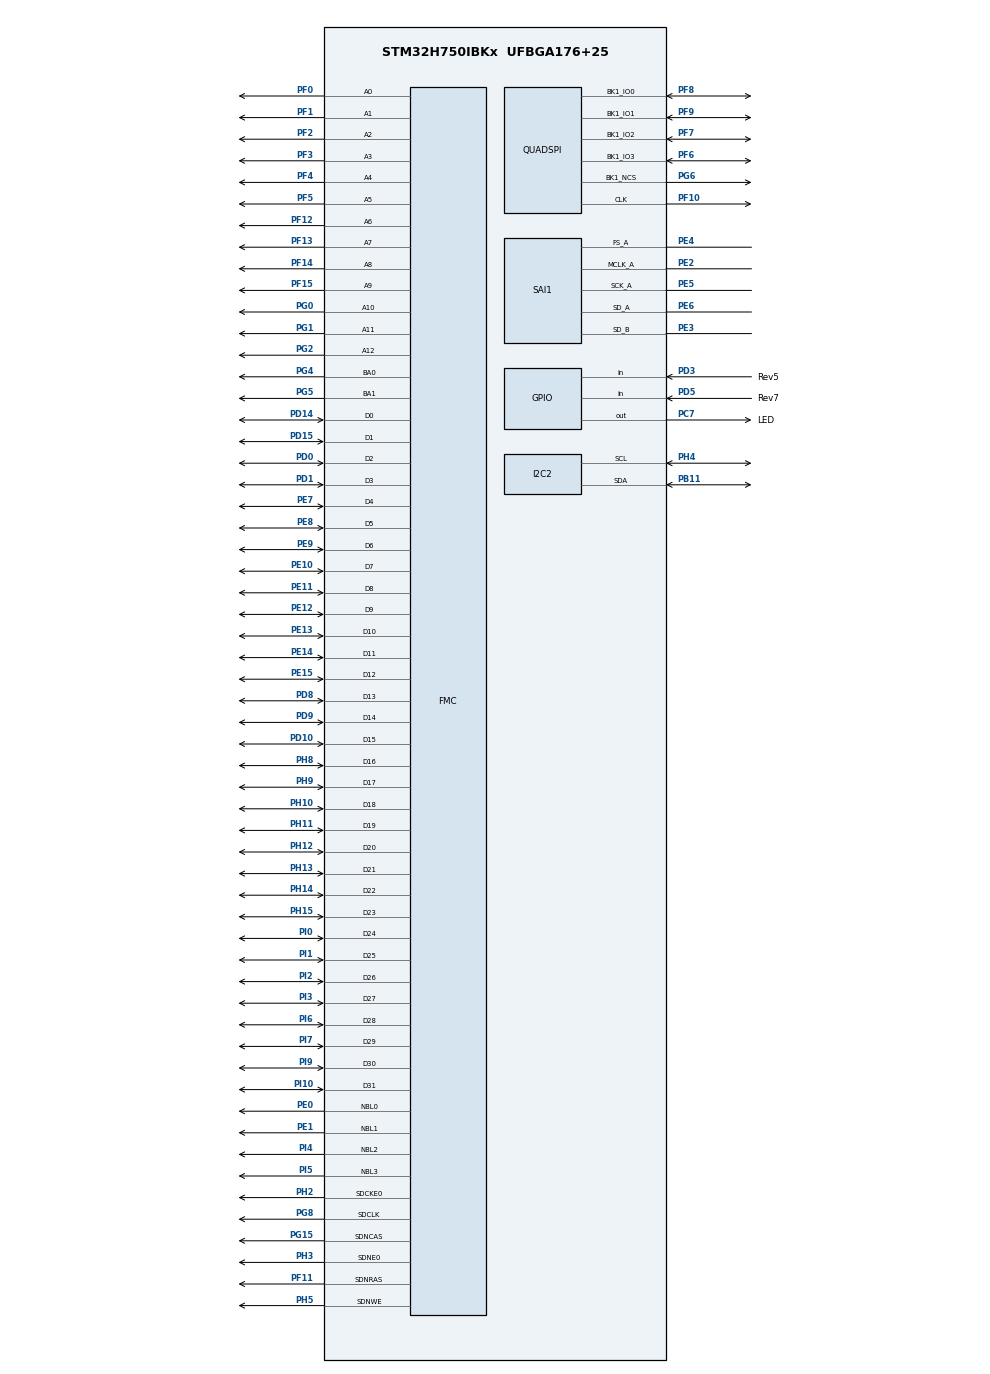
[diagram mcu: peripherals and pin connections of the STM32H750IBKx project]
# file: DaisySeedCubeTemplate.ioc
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CORTEX_M7.AccessPermission_S-Cortex_Memory_Protection_Unit_Region1_Settings_S=MPU_REGION_PRIV_RO
CORTEX_M7.AccessPermission_S-Cortex_Memory_Protection_Unit_Region2_Settings_S=MPU_REGION_FULL_ACCESS
CORTEX_M7.AccessPermission_S-Cortex_Memory_Protection_Unit_Region3_Settings_S=MPU_REGION_FULL_ACCESS
CORTEX_M7.AccessPermission_S-Cortex_Memory_Protection_Unit_Region4_Settings_S=MPU_REGION_FULL_ACCESS
CORTEX_M7.AccessPermission_S-Cortex_Memory_Protection_Unit_Region5_Settings_S=MPU_REGION_FULL_ACCESS
CORTEX_M7.AccessPermission_S-Cortex_Memory_Protection_Unit_Region6_Settings_S=MPU_REGION_FULL_ACCESS
CORTEX_M7.AccessPermission_S-Cortex_Memory_Protection_Unit_Region7_Settings_S=MPU_REGION_PRIV_RO_URO
CORTEX_M7.AccessPermission_S-Cortex_Memory_Protection_Unit_Region8_Settings_S=MPU_REGION_FULL_ACCESS
CORTEX_M7.BaseAddress_S-Cortex_Memory_Protection_Unit_Region1_Settings_S=0x08000000
CORTEX_M7.BaseAddress_S-Cortex_Memory_Protection_Unit_Region2_Settings_S=0x24070800
CORTEX_M7.BaseAddress_S-Cortex_Memory_Protection_Unit_Region3_Settings_S=0x24071000
CORTEX_M7.BaseAddress_S-Cortex_Memory_Protection_Unit_Region4_Settings_S=0x24072000
CORTEX_M7.BaseAddress_S-Cortex_Memory_Protection_Unit_Region5_Settings_S=0x24074000
CORTEX_M7.BaseAddress_S-Cortex_Memory_Protection_Unit_Region6_Settings_S=0x24078000
CORTEX_M7.BaseAddress_S-Cortex_Memory_Protection_Unit_Region7_Settings_S=0x90000000
CORTEX_M7.BaseAddress_S-Cortex_Memory_Protection_Unit_Region8_Settings_S=0xC0000000
CORTEX_M7.DisableExec_S-Cortex_Memory_Protection_Unit_Region7_Settings_S=MPU_INSTRUCTION_ACCESS_DISABLE
CORTEX_M7.DisableExec_S-Cortex_Memory_Protection_Unit_Region8_Settings_S=MPU_INSTRUCTION_ACCESS_DISABLE
CORTEX_M7.Enable_S-Cortex_Memory_Protection_Unit_Region1_Settings_S=MPU_REGION_ENABLE
CORTEX_M7.Enable_S-Cortex_Memory_Protection_Unit_Region2_Settings_S=MPU_REGION_ENABLE
CORTEX_M7.Enable_S-Cortex_Memory_Protection_Unit_Region3_Settings_S=MPU_REGION_ENABLE
CORTEX_M7.Enable_S-Cortex_Memory_Protection_Unit_Region4_Settings_S=MPU_REGION_ENABLE
CORTEX_M7.Enable_S-Cortex_Memory_Protection_Unit_Region5_Settings_S=MPU_REGION_ENABLE
CORTEX_M7.Enable_S-Cortex_Memory_Protection_Unit_Region6_Settings_S=MPU_REGION_ENABLE
CORTEX_M7.Enable_S-Cortex_Memory_Protection_Unit_Region7_Settings_S=MPU_REGION_ENABLE
CORTEX_M7.Enable_S-Cortex_Memory_Protection_Unit_Region8_Settings_S=MPU_REGION_ENABLE
CORTEX_M7.IsCacheable_S-Cortex_Memory_Protection_Unit_Region1_Settings_S=MPU_ACCESS_CACHEABLE
CORTEX_M7.IsShareable_S-Cortex_Memory_Protection_Unit_Region2_Settings_S=MPU_ACCESS_SHAREABLE
CORTEX_M7.IsShareable_S-Cortex_Memory_Protection_Unit_Region3_Settings_S=MPU_ACCESS_SHAREABLE
CORTEX_M7.IsShareable_S-Cortex_Memory_Protection_Unit_Region4_Settings_S=MPU_ACCESS_SHAREABLE
CORTEX_M7.IsShareable_S-Cortex_Memory_Protection_Unit_Region5_Settings_S=MPU_ACCESS_SHAREABLE
CORTEX_M7.IsShareable_S-Cortex_Memory_Protection_Unit_Region6_Settings_S=MPU_ACCESS_SHAREABLE
CORTEX_M7.IsShareable_S-Cortex_Memory_Protection_Unit_Region7_Settings_S=MPU_ACCESS_SHAREABLE
CORTEX_M7.IsShareable_S-Cortex_Memory_Protection_Unit_Region8_Settings_S=MPU_ACCESS_SHAREABLE
CORTEX_M7.MPU_Control=__NULL
CORTEX_M7.Number_S-Cortex_Memory_Protection_Unit_Region2_Settings_S=MPU_REGION_NUMBER2
CORTEX_M7.Number_S-Cortex_Memory_Protection_Unit_Region3_Settings_S=MPU_REGION_NUMBER3
CORTEX_M7.Number_S-Cortex_Memory_Protection_Unit_Region4_Settings_S=MPU_REGION_NUMBER4
CORTEX_M7.Number_S-Cortex_Memory_Protection_Unit_Region5_Settings_S=MPU_REGION_NUMBER5
CORTEX_M7.Number_S-Cortex_Memory_Protection_Unit_Region6_Settings_S=MPU_REGION_NUMBER6
CORTEX_M7.Number_S-Cortex_Memory_Protection_Unit_Region7_Settings_S=MPU_REGION_NUMBER7
CORTEX_M7.Number_S-Cortex_Memory_Protection_Unit_Region8_Settings_S=MPU_REGION_NUMBER8
CORTEX_M7.Size_S-Cortex_Memory_Protection_Unit_Region1_Settings_S=MPU_REGION_SIZE_128KB
CORTEX_M7.Size_S-Cortex_Memory_Protection_Unit_Region2_Settings_S=MPU_REGION_SIZE_2KB
CORTEX_M7.Size_S-Cortex_Memory_Protection_Unit_Region3_Settings_S=MPU_REGION_SIZE_4KB
CORTEX_M7.Size_S-Cortex_Memory_Protection_Unit_Region4_Settings_S=MPU_REGION_SIZE_8KB
CORTEX_M7.Size_S-Cortex_Memory_Protection_Unit_Region5_Settings_S=MPU_REGION_SIZE_16KB
CORTEX_M7.Size_S-Cortex_Memory_Protection_Unit_Region6_Settings_S=MPU_REGION_SIZE_32KB
CORTEX_M7.Size_S-Cortex_Memory_Protection_Unit_Region7_Settings_S=MPU_REGION_SIZE_8MB
CORTEX_M7.Size_S-Cortex_Memory_Protection_Unit_Region8_Settings_S=MPU_REGION_SIZE_64MB
CORTEX_M7.TypeExtField_S-Cortex_Memory_Protection_Unit_Region2_Settings_S=MPU_TEX_LEVEL1
CORTEX_M7.TypeExtField_S-Cortex_Memory_Protection_Unit_Region3_Settings_S=MPU_TEX_LEVEL1
CORTEX_M7.TypeExtField_S-Cortex_Memory_Protection_Unit_Region4_Settings_S=MPU_TEX_LEVEL1
CORTEX_M7.TypeExtField_S-Cortex_Memory_Protection_Unit_Region5_Settings_S=MPU_TEX_LEVEL1
CORTEX_M7.TypeExtField_S-Cortex_Memory_Protection_Unit_Region6_Settings_S=MPU_TEX_LEVEL1
CORTEX_M7.TypeExtField_S-Cortex_Memory_Protection_Unit_Region7_Settings_S=MPU_TEX_LEVEL1
CORTEX_M7.TypeExtField_S-Cortex_Memory_Protection_Unit_Region8_Settings_S=MPU_TEX_LEVEL1
CORTEX_M7.default_mode_Activation=0
Dma.Request0=SAI1_A
Dma.Request1=SAI1_B
Dma.SAI1_A.0.Direction=DMA_MEMORY_TO_PERIPH
Dma.SAI1_A.0.EventEnable=DISABLE
Dma.SAI1_A.0.FIFOMode=DMA_FIFOMODE_DISABLE
Dma.SAI1_A.0.Instance=DMA1_Stream0
Dma.SAI1_A.0.MemDataAlignment=DMA_MDATAALIGN_WORD
Dma.SAI1_A.0.MemInc=DMA_MINC_ENABLE
Dma.SAI1_A.0.Mode=DMA_CIRCULAR
Dma.SAI1_A.0.PeriphDataAlignment=DMA_PDATAALIGN_WORD
Dma.SAI1_A.0.PeriphInc=DMA_PINC_DISABLE
Dma.SAI1_A.0.Polarity=HAL_DMAMUX_REQ_GEN_RISING
Dma.SAI1_A.0.Priority=DMA_PRIORITY_HIGH
Dma.SAI1_A.0.RequestNumber=1
Dma.SAI1_A.0.SignalID=NONE
Dma.SAI1_A.0.SyncEnable=DISABLE
Dma.SAI1_A.0.SyncPolarity=HAL_DMAMUX_SYNC_NO_EVENT
Dma.SAI1_A.0.SyncRequestNumber=1
Dma.SAI1_A.0.SyncSignalID=NONE
Dma.SAI1_B.1.Direction=DMA_PERIPH_TO_MEMORY
Dma.SAI1_B.1.EventEnable=DISABLE
Dma.SAI1_B.1.FIFOMode=DMA_FIFOMODE_DISABLE
Dma.SAI1_B.1.Instance=DMA1_Stream1
Dma.SAI1_B.1.MemDataAlignment=DMA_MDATAALIGN_WORD
Dma.SAI1_B.1.MemInc=DMA_MINC_ENABLE
Dma.SAI1_B.1.Mode=DMA_CIRCULAR
Dma.SAI1_B.1.PeriphDataAlignment=DMA_PDATAALIGN_WORD
Dma.SAI1_B.1.PeriphInc=DMA_PINC_DISABLE
Dma.SAI1_B.1.Polarity=HAL_DMAMUX_REQ_GEN_RISING
Dma.SAI1_B.1.Priority=DMA_PRIORITY_LOW
Dma.SAI1_B.1.RequestNumber=1
Dma.SAI1_B.1.SignalID=NONE
Dma.SAI1_B.1.SyncEnable=DISABLE
Dma.SAI1_B.1.SyncPolarity=HAL_DMAMUX_SYNC_NO_EVENT
Dma.SAI1_B.1.SyncRequestNumber=1
Dma.SAI1_B.1.SyncSignalID=NONE
FMC.CASLatency1=FMC_SDRAM_CAS_LATENCY_3
FMC.ColumnBitsNumber1=FMC_SDRAM_COLUMN_BITS_NUM_9
FMC.ExitSelfRefreshDelay1=7
FMC.LoadToActiveDelay1=2
FMC.RCDDelay1=10
FMC.ReadBurst1=FMC_SDRAM_RBURST_ENABLE
FMC.ReadPipeDelay1=FMC_SDRAM_RPIPE_DELAY_0
FMC.RowCycleDelay1=8
FMC.SDClockPeriod1=FMC_SDRAM_CLOCK_PERIOD_2
FMC.SelfRefreshTime1=4
FMC.WriteRecoveryTime1=3
I2C2.Timing=0x307075B1
Mcu.Family=STM32H7
Mcu.Name=STM32H750IBKx
Mcu.Package=UFBGA176+25
NVIC.DMA1_Stream0_IRQn=true\:0\:0\:false\:false\:true\:false\:true\:true
NVIC.DMA1_Stream1_IRQn=true\:0\:0\:false\:false\:true\:false\:true\:true
NVIC.FMC_IRQn=true\:0\:0\:false\:false\:true\:true\:true\:true
NVIC.I2C2_ER_IRQn=true\:0\:0\:false\:false\:true\:true\:true\:true
NVIC.I2C2_EV_IRQn=true\:0\:0\:false\:false\:true\:true\:true\:true
NVIC.PriorityGroup=NVIC_PRIORITYGROUP_4
NVIC.QUADSPI_IRQn=true\:0\:0\:false\:false\:true\:true\:true\:true
PA13\ (JTMS/SWDIO).Mode=JTAG_4_pins
PA13\ (JTMS/SWDIO).Signal=DEBUG_JTMS-SWDIO
PA14\ (JTCK/SWCLK).Mode=JTAG_4_pins
PA14\ (JTCK/SWCLK).Signal=DEBUG_JTCK-SWCLK
PA15\ (JTDI).Mode=JTAG_4_pins
PA15\ (JTDI).Signal=DEBUG_JTDI
PB11.Mode=I2C
PB11.Signal=I2C2_SDA
PB3\ (JTDO/TRACESWO).Mode=JTAG_4_pins
PB3\ (JTDO/TRACESWO).Signal=DEBUG_JTDO-SWO
PC7.GPIO_Label=LED
PC7.Signal=GPIO_Output
PD0.Signal=FMC_D2_DA2
PD1.Signal=FMC_D3_DA3
PD10.Signal=FMC_D15_DA15
PD14.Signal=FMC_D0_DA0
PD15.Signal=FMC_D1_DA1
PD3.GPIO_Label=Rev5
PD3.GPIO_PuPd=GPIO_PULLUP
PD3.Signal=GPIO_Input
PD5.GPIO_Label=Rev7
PD5.GPIO_PuPd=GPIO_PULLUP
PD5.Signal=GPIO_Input
PD8.Signal=FMC_D13_DA13
PD9.Signal=FMC_D14_DA14
PE0.Signal=FMC_NBL0
PE1.Signal=FMC_NBL1
PE10.Signal=FMC_D7_DA7
PE11.Signal=FMC_D8_DA8
PE12.Signal=FMC_D9_DA9
PE13.Signal=FMC_D10_DA10
PE14.Signal=FMC_D11_DA11
PE15.Signal=FMC_D12_DA12
PE2.GPIO_Speed=GPIO_SPEED_FREQ_VERY_HIGH
PE2.Mode=SAI_A_MasterWithClock
PE2.Signal=SAI1_MCLK_A
PE3.GPIO_Speed=GPIO_SPEED_FREQ_VERY_HIGH
PE3.Mode=SAI_B_SyncSlave
PE3.Signal=SAI1_SD_B
PE4.GPIO_Speed=GPIO_SPEED_FREQ_VERY_HIGH
PE4.Mode=SAI_A_MasterWithClock
PE4.Signal=SAI1_FS_A
PE5.GPIO_Speed=GPIO_SPEED_FREQ_VERY_HIGH
PE5.Mode=SAI_A_MasterWithClock
PE5.Signal=SAI1_SCK_A
PE6.GPIO_Speed=GPIO_SPEED_FREQ_VERY_HIGH
PE6.Mode=SAI_A_MasterWithClock
PE6.Signal=SAI1_SD_A
PE7.Signal=FMC_D4_DA4
PE8.Signal=FMC_D5_DA5
PE9.Signal=FMC_D6_DA6
PF0.Signal=FMC_A0
PF1.Signal=FMC_A1
PF10.GPIO_Speed=GPIO_SPEED_FREQ_VERY_HIGH
PF10.Mode=Single Bank 1
PF10.Signal=QUADSPI_CLK
PF11.Signal=FMC_SDNRAS
PF12.Signal=FMC_A6
PF13.Signal=FMC_A7
PF14.Signal=FMC_A8
PF15.Signal=FMC_A9
PF2.Signal=FMC_A2
PF3.Signal=FMC_A3
PF4.Signal=FMC_A4
PF5.Signal=FMC_A5
PF6.GPIO_Speed=GPIO_SPEED_FREQ_VERY_HIGH
PF6.Mode=Single Bank 1
PF6.Signal=QUADSPI_BK1_IO3
PF7.GPIO_Speed=GPIO_SPEED_FREQ_VERY_HIGH
PF7.Mode=Single Bank 1
PF7.Signal=QUADSPI_BK1_IO2
PF8.GPIO_Speed=GPIO_SPEED_FREQ_VERY_HIGH
PF8.Mode=Single Bank 1
PF8.Signal=QUADSPI_BK1_IO0
PF9.GPIO_Speed=GPIO_SPEED_FREQ_VERY_HIGH
PF9.Mode=Single Bank 1
PF9.Signal=QUADSPI_BK1_IO1
PG0.Signal=FMC_A10
PG1.Signal=FMC_A11
PG15.Signal=FMC_SDNCAS
PG2.Signal=FMC_A12
PG4.Signal=FMC_A14_BA0
PG5.Signal=FMC_A15_BA1
PG6.GPIO_Speed=GPIO_SPEED_FREQ_VERY_HIGH
PG6.Mode=Single Bank 1
PG6.Signal=QUADSPI_BK1_NCS
PG8.Signal=FMC_SDCLK
PH0-OSC_IN\ (PH0).Mode=HSE-External-Oscillator
PH0-OSC_IN\ (PH0).Signal=RCC_OSC_IN
PH1-OSC_OUT\ (PH1).Mode=HSE-External-Oscillator
PH1-OSC_OUT\ (PH1).Signal=RCC_OSC_OUT
PH10.Signal=FMC_D18
PH11.Signal=FMC_D19
PH12.Signal=FMC_D20
PH13.Signal=FMC_D21
PH14.Signal=FMC_D22
PH15.Signal=FMC_D23
PH2.Mode=SdramChipSelect1_1
PH2.Signal=FMC_SDCKE0
PH3.Mode=SdramChipSelect1_1
PH3.Signal=FMC_SDNE0
PH4.Mode=I2C
PH4.Signal=I2C2_SCL
PH5.Signal=FMC_SDNWE
PH8.Signal=FMC_D16
PH9.Signal=FMC_D17
PI0.Signal=FMC_D24
PI1.Signal=FMC_D25
PI10.Signal=FMC_D31
PI2.Signal=FMC_D26
PI3.Signal=FMC_D27
PI4.Signal=FMC_NBL2
PI5.Signal=FMC_NBL3
PI6.Signal=FMC_D28
PI7.Signal=FMC_D29
PI9.Signal=FMC_D30
ProjectManager.HeapSize=0x8000
ProjectManager.StackSize=0x2000
ProjectManager.TargetToolchain=STM32CubeIDE
QUADSPI.ChipSelectHighTime=QSPI_CS_HIGH_TIME_1_CYCLE
QUADSPI.ClockPrescaler=2
QUADSPI.DeviceType=SPI_DEVICE_FLASH
QUADSPI.FlashSize=22
QUADSPI.SampleShifting=QSPI_SAMPLE_SHIFTING_HALFCYCLE
RCC.ADCFreq_Value=12288026.75189394
RCC.APB1Freq_Value=120000000
RCC.APB2Freq_Value=120000000
RCC.APB3Freq_Value=120000000
RCC.APB4Freq_Value=120000000
RCC.CortexFreq_Value=480000000
RCC.D1PPRE=RCC_APB3_DIV2
RCC.D2PPRE1=RCC_APB1_DIV2
RCC.D2PPRE2=RCC_APB2_DIV2
RCC.D3PPRE=RCC_APB4_DIV2
RCC.DIVM1=4
RCC.DIVM2=1
RCC.DIVN1=240
RCC.DIVN2=50
RCC.DIVP2=66
RCC.DIVQ1=6
RCC.DIVR1=8
RCC.HCLKFreq_Value=240000000
RCC.HPRE=RCC_HCLK_DIV2
RCC.HSE_VALUE=16000000
RCC.PLL2FRACN=5637
RCC.PLLFRACN=0
RCC.PLLSourceVirtual=RCC_PLLSOURCE_HSE
RCC.SAI1CLockSelection=RCC_SAI1CLKSOURCE_PLL2
RCC.SYSCLKFreq_VALUE=480000000
RCC.SYSCLKSource=RCC_SYSCLKSOURCE_PLLCLK
RCC.USBFreq_Value=160000000
SAI1.AudioFrequency-SAI_A_MasterWithClock=SAI_AUDIO_FREQUENCY_48K
SAI1.BasicDataSize-SAI_A_MasterWithClock=SAI_PROTOCOL_DATASIZE_24BIT
SAI1.BasicDataSize-SAI_B_SyncSlave=SAI_PROTOCOL_DATASIZE_24BIT
SAI1.BasicProtocol-SAI_A_MasterWithClock=SAI_I2S_MSBJUSTIFIED
SAI1.BasicProtocol-SAI_B_SyncSlave=SAI_I2S_MSBJUSTIFIED
SAI1.ErrorAudioFreq-SAI_A_MasterWithClock=0.0 %
SAI1.InitProtocol-SAI_A_MasterWithClock=Enable
SAI1.InitProtocol-SAI_B_SyncSlave=Enable
SAI1.Instance-SAI_A_MasterWithClock=SAI$Index_Block_A
SAI1.Instance-SAI_B_SyncSlave=SAI$Index_Block_B
SAI1.MClockEnable-SAI_A_MasterWithClock=SAI_MASTERCLOCK_ENABLE
SAI1.NoDivider-SAI_A_MasterWithClock=SAI_MCK_OVERSAMPLING_DISABLE
SAI1.RealAudioFreq-SAI_A_MasterWithClock=48.0 KHz
SAI1.VirtualMode-SAI_A_MasterWithClock=VM_MASTER
SAI1.VirtualMode-SAI_B_SyncSlave=VM_SLAVE
SAI1.VirtualProtocol-SAI_A_BASIC=VM_BASIC_PROTOCOL
SAI1.VirtualProtocol-SAI_B_BASIC=VM_BASIC_PROTOCOL
SH.FMC_A0.0=FMC_A0,13b-sda1
SH.FMC_A1.0=FMC_A1,13b-sda1
SH.FMC_A10.0=FMC_A10,13b-sda1
SH.FMC_A11.0=FMC_A11,13b-sda1
SH.FMC_A12.0=FMC_A12,13b-sda1
SH.FMC_A14_BA0.0=FMC_BA0,FourSdramBanks1
SH.FMC_A15_BA1.0=FMC_BA1,FourSdramBanks1
SH.FMC_A2.0=FMC_A2,13b-sda1
SH.FMC_A3.0=FMC_A3,13b-sda1
SH.FMC_A4.0=FMC_A4,13b-sda1
SH.FMC_A5.0=FMC_A5,13b-sda1
SH.FMC_A6.0=FMC_A6,13b-sda1
SH.FMC_A7.0=FMC_A7,13b-sda1
SH.FMC_A8.0=FMC_A8,13b-sda1
SH.FMC_A9.0=FMC_A9,13b-sda1
SH.FMC_D0_DA0.0=FMC_D0,sd-32b-d1
SH.FMC_D10_DA10.0=FMC_D10,sd-32b-d1
SH.FMC_D11_DA11.0=FMC_D11,sd-32b-d1
SH.FMC_D12_DA12.0=FMC_D12,sd-32b-d1
SH.FMC_D13_DA13.0=FMC_D13,sd-32b-d1
SH.FMC_D14_DA14.0=FMC_D14,sd-32b-d1
SH.FMC_D15_DA15.0=FMC_D15,sd-32b-d1
SH.FMC_D16.0=FMC_D16,sd-32b-d1
SH.FMC_D17.0=FMC_D17,sd-32b-d1
SH.FMC_D18.0=FMC_D18,sd-32b-d1
SH.FMC_D19.0=FMC_D19,sd-32b-d1
SH.FMC_D1_DA1.0=FMC_D1,sd-32b-d1
SH.FMC_D20.0=FMC_D20,sd-32b-d1
SH.FMC_D21.0=FMC_D21,sd-32b-d1
SH.FMC_D22.0=FMC_D22,sd-32b-d1
SH.FMC_D23.0=FMC_D23,sd-32b-d1
SH.FMC_D24.0=FMC_D24,sd-32b-d1
SH.FMC_D25.0=FMC_D25,sd-32b-d1
SH.FMC_D26.0=FMC_D26,sd-32b-d1
SH.FMC_D27.0=FMC_D27,sd-32b-d1
SH.FMC_D28.0=FMC_D28,sd-32b-d1
SH.FMC_D29.0=FMC_D29,sd-32b-d1
SH.FMC_D2_DA2.0=FMC_D2,sd-32b-d1
SH.FMC_D30.0=FMC_D30,sd-32b-d1
SH.FMC_D31.0=FMC_D31,sd-32b-d1
SH.FMC_D3_DA3.0=FMC_D3,sd-32b-d1
SH.FMC_D4_DA4.0=FMC_D4,sd-32b-d1
SH.FMC_D5_DA5.0=FMC_D5,sd-32b-d1
SH.FMC_D6_DA6.0=FMC_D6,sd-32b-d1
SH.FMC_D7_DA7.0=FMC_D7,sd-32b-d1
SH.FMC_D8_DA8.0=FMC_D8,sd-32b-d1
SH.FMC_D9_DA9.0=FMC_D9,sd-32b-d1
SH.FMC_NBL0.0=FMC_NBL0,Sd4ByteEnable1
SH.FMC_NBL1.0=FMC_NBL1,Sd4ByteEnable1
SH.FMC_NBL2.0=FMC_NBL2,Sd4ByteEnable1
SH.FMC_NBL3.0=FMC_NBL3,Sd4ByteEnable1
SH.FMC_SDCLK.0=FMC_SDCLK,13b-sda1
SH.FMC_SDNCAS.0=FMC_SDNCAS,13b-sda1
SH.FMC_SDNRAS.0=FMC_SDNRAS,13b-sda1
SH.FMC_SDNWE.0=FMC_SDNWE,13b-sda1
VP_MEMORYMAP_VS_MEMORYMAP.Mode=CurAppReg
VP_SAI1_VP_$IpInstance_SAIA_SAI_BASIC.Mode=SAI_A_BASIC
VP_SAI1_VP_$IpInstance_SAIB_SAI_BASIC.Mode=SAI_B_BASIC
board=custom

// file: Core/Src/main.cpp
/* USER CODE BEGIN Header */
/**
  ******************************************************************************
  * @file           : main.c
  * @brief          : Main program body
  ******************************************************************************
  * @attention
  *
  * Copyright (c) 2025 STMicroelectronics.
  * All rights reserved.
  *
  * This software is licensed under terms that can be found in the LICENSE file
  * in the root directory of this software component.
  * If no LICENSE file comes with this software, it is provided AS-IS.
  *
  ******************************************************************************
  */
/* USER CODE END Header */
#include "main.h"

/* USER CODE BEGIN Includes */
#include "cIS25LPxxx.h"
#include "cWM8731.h"
/* USER CODE END Includes */

I2C_HandleTypeDef hi2c2;

QSPI_HandleTypeDef hqspi;

SAI_HandleTypeDef hsai_BlockA1;
SAI_HandleTypeDef hsai_BlockB1;
DMA_HandleTypeDef hdma_sai1_a;
DMA_HandleTypeDef hdma_sai1_b;

SDRAM_HandleTypeDef hsdram1;

void SystemClock_Config(void);
void PeriphCommonClock_Config(void);

/* USER CODE BEGIN 0 */

// == DAD =================================================================

extern "C" void DAD_MPU_Config(void);

//QFlash
Dad::cIS25LPxxx __Flash;

// Revision
enum HardRev{
	Rev5,
	Rev7
}__HardRev;

// WM8731 management for Rev5
Dad::cWM8731  __WM8731;

// Test SDRAM
SDRAM_SECTION uint8_t TabSRAMTest[100];

//------------------------------------------------------------------
// AudioCallback
uint32_t __CT=0; 			// Cycle counter
							// - Used in main loop to blink an activity LED
 	 	 	 	 	 	 	// - The LED blink rate indicates proper callback execution
ITCM void AudioCallback(AudioBuffer *pIn, AudioBuffer *pOut){
	for (size_t i = 0; i < AUDIO_BUFFER_SIZE; i++)
	{
		pOut->Right = pIn->Right;
		pOut->Left = pIn->Left;
		pOut++;
		pIn++;
	}

    // Increment cycle counter for visual feedback:
    __CT++;
}

// ------------------------------------------------------------------------
// Function to copy code from Flash to ITCM RAM at startup
// This ensures that critical code runs from ITCM for better performance.
//
// Any critical function that needs to run from ITCM must be preceded by the ITCM macro.
// Example usage:
//     ITCM void CriticalFunction() {
//         // Time-sensitive code
//     }
// ------------------------------------------------------------------------
#pragma GCC push_options
#pragma GCC optimize ("O0")
extern uint32_t __sITCM, __eITCM, __lITCM;  // Linker symbols for ITCM section

void Copy_ITCM_Code(void) {
    uint32_t *pSrc = &__lITCM;  // Source address in Flash (load address)
    uint32_t *pDest = &__sITCM; // Destination address in ITCM RAM (start of ITCM)

    // Copy the code section from Flash to ITCM RAM
    while (pDest < &__eITCM) {
        *pDest++ = *pSrc++;
    }
}
#pragma GCC pop_options

// ------------------------------------------------------------------------
// Specific initialization for hardware revision 5:
// input and output signals are inverted compared to revision 7."
extern "C" void HAL_SAIRev5_MspInit(SAI_HandleTypeDef* hsai);
void MX_SAI1Rev5_Init(void)
{
  HAL_SAI_RegisterCallback(&hsai_BlockA1, HAL_SAI_MSPINIT_CB_ID,HAL_SAIRev5_MspInit);
  HAL_SAI_RegisterCallback(&hsai_BlockB1, HAL_SAI_MSPINIT_CB_ID,HAL_SAIRev5_MspInit);

  hsai_BlockA1.Instance = SAI1_Block_A;
  // ===============================================
  // Dad Change TX->RX
  hsai_BlockA1.Init.AudioMode = SAI_MODEMASTER_RX;
  hsai_BlockA1.Init.Synchro = SAI_ASYNCHRONOUS;
  hsai_BlockA1.Init.OutputDrive = SAI_OUTPUTDRIVE_DISABLE;
  hsai_BlockA1.Init.NoDivider = SAI_MCK_OVERSAMPLING_DISABLE;
  hsai_BlockA1.Init.MckOverSampling = SAI_MCK_OVERSAMPLING_DISABLE;
  hsai_BlockA1.Init.FIFOThreshold = SAI_FIFOTHRESHOLD_EMPTY;
  hsai_BlockA1.Init.AudioFrequency = SAI_AUDIO_FREQUENCY_48K;
  hsai_BlockA1.Init.SynchroExt = SAI_SYNCEXT_DISABLE;
  hsai_BlockA1.Init.MonoStereoMode = SAI_STEREOMODE;
  hsai_BlockA1.Init.CompandingMode = SAI_NOCOMPANDING;
  hsai_BlockA1.Init.TriState = SAI_OUTPUT_NOTRELEASED;
  if (HAL_SAI_InitProtocol(&hsai_BlockA1, SAI_I2S_MSBJUSTIFIED, SAI_PROTOCOL_DATASIZE_24BIT, 2) != HAL_OK)
  {
    Error_Handler();
  }
  hsai_BlockB1.Instance = SAI1_Block_B;
  // ===============================================
  // Dad Change RC->TX
  hsai_BlockB1.Init.AudioMode = SAI_MODESLAVE_TX;
  hsai_BlockB1.Init.Synchro = SAI_SYNCHRONOUS;
  hsai_BlockB1.Init.OutputDrive = SAI_OUTPUTDRIVE_DISABLE;
  hsai_BlockB1.Init.MckOverSampling = SAI_MCK_OVERSAMPLING_DISABLE;
  hsai_BlockB1.Init.FIFOThreshold = SAI_FIFOTHRESHOLD_EMPTY;
  hsai_BlockB1.Init.SynchroExt = SAI_SYNCEXT_DISABLE;
  hsai_BlockB1.Init.MonoStereoMode = SAI_STEREOMODE;
  hsai_BlockB1.Init.CompandingMode = SAI_NOCOMPANDING;
  hsai_BlockB1.Init.TriState = SAI_OUTPUT_NOTRELEASED;
  if (HAL_SAI_InitProtocol(&hsai_BlockB1, SAI_I2S_MSBJUSTIFIED, SAI_PROTOCOL_DATASIZE_24BIT, 2) != HAL_OK)
  {
    Error_Handler();
  }
}

// ===================================================================

/* USER CODE END 0 */

int main(void)
{

  /* USER CODE BEGIN 1 */

// ==** DAD **=================================================================

#ifdef USE_RAM
	SCB->VTOR = 0x24000000;
#endif

// ===================================================================

  /* USER CODE END 1 */

  /* MCU Configuration--------------------------------------------------------*/

  /* Reset of all peripherals, Initializes the Flash interface and the Systick. */
  HAL_Init();

  /* Configure the system clock */
  SystemClock_Config();

  /* Configure the peripherals common clocks */
  PeriphCommonClock_Config();

  /* Initialize all configured peripherals */
  MX_GPIO_Init();
  MX_DMA_Init();
  MX_QUADSPI_Init();
  MX_FMC_Init();
  /* USER CODE BEGIN 2 */

// ==** DAD **=================================================================
  __Flash.Init(&hqspi);
  Copy_ITCM_Code();
  DAD_MPU_Config();
  SCB_EnableICache();
  SCB_EnableDCache();

  // Revision configuration
  MX_DMA_Init();
  if(GPIO_PIN_RESET == HAL_GPIO_ReadPin(Rev5_GPIO_Port, Rev5_Pin)){
	  __HardRev = Rev5;
	  MX_I2C2_Init();
	  MX_SAI1Rev5_Init();
	  __WM8731.Initialize(&hi2c2);
  }else if(GPIO_PIN_RESET == HAL_GPIO_ReadPin(Rev7_GPIO_Port, Rev7_Pin)){
	  __HardRev = Rev7;
	  MX_SAI1_Init();
	  GPIO_InitTypeDef GPIO_InitStruct = {0};
	  GPIO_InitStruct.Pin = GPIO_PIN_11;
	  GPIO_InitStruct.Mode = GPIO_MODE_OUTPUT_PP;
	  GPIO_InitStruct.Pull = GPIO_NOPULL;
	  GPIO_InitStruct.Speed = GPIO_SPEED_FREQ_LOW;
	  HAL_GPIO_Init(GPIOB, &GPIO_InitStruct);
	  HAL_GPIO_WritePin(GPIOB, GPIO_PIN_11, GPIO_PIN_RESET);
  }else{
	  // Revision not supported
	  while(1){
		    HAL_GPIO_TogglePin(LED_GPIO_Port, LED_Pin);
			HAL_Delay(100);
	  }
  }
  StartAudio();

  // Test SDRAM
  for(uint8_t Index=0; Index < 100; Index++){
	TabSRAMTest[Index] = Index;
  }

// ===================================================================

  /* USER CODE END 2 */

  /* Infinite loop */
  while (1)
  {

    /* USER CODE BEGIN 3 */

// ==** DAD **=================================================================

      // LED blinking: indicates that the audio loop is operating correctly.
      if(__CT >= (uint32_t) (((float)SAMPLING_RATE / 4.0f)  * 0.5f)){
    	  __CT =0;
    	  HAL_GPIO_TogglePin(LED_GPIO_Port, LED_Pin);
      }

	  HAL_Delay(100);

// ===================================================================

  }
  /* USER CODE END 3 */
}

void SystemClock_Config(void)
{
  RCC_OscInitTypeDef RCC_OscInitStruct = {0};
  RCC_ClkInitTypeDef RCC_ClkInitStruct = {0};

  /** Supply configuration update enable
  */
  HAL_PWREx_ConfigSupply(PWR_LDO_SUPPLY);

  /** Configure the main internal regulator output voltage
  */
  __HAL_PWR_VOLTAGESCALING_CONFIG(PWR_REGULATOR_VOLTAGE_SCALE0);

  while(!__HAL_PWR_GET_FLAG(PWR_FLAG_VOSRDY)) {}

  /** Initializes the RCC Oscillators according to the specified parameters
  * in the RCC_OscInitTypeDef structure.
  */
  RCC_OscInitStruct.OscillatorType = RCC_OSCILLATORTYPE_HSE;
  RCC_OscInitStruct.HSEState = RCC_HSE_ON;
  RCC_OscInitStruct.PLL.PLLState = RCC_PLL_ON;
  RCC_OscInitStruct.PLL.PLLSource = RCC_PLLSOURCE_HSE;
  RCC_OscInitStruct.PLL.PLLM = 4;
  RCC_OscInitStruct.PLL.PLLN = 240;
  RCC_OscInitStruct.PLL.PLLP = 2;
  RCC_OscInitStruct.PLL.PLLQ = 6;
  RCC_OscInitStruct.PLL.PLLR = 8;
  RCC_OscInitStruct.PLL.PLLRGE = RCC_PLL1VCIRANGE_2;
  RCC_OscInitStruct.PLL.PLLVCOSEL = RCC_PLL1VCOWIDE;
  RCC_OscInitStruct.PLL.PLLFRACN = 0;
  if (HAL_RCC_OscConfig(&RCC_OscInitStruct) != HAL_OK)
  {
    Error_Handler();
  }

  /** Initializes the CPU, AHB and APB buses clocks
  */
  RCC_ClkInitStruct.ClockType = RCC_CLOCKTYPE_HCLK|RCC_CLOCKTYPE_SYSCLK
                              |RCC_CLOCKTYPE_PCLK1|RCC_CLOCKTYPE_PCLK2
                              |RCC_CLOCKTYPE_D3PCLK1|RCC_CLOCKTYPE_D1PCLK1;
  RCC_ClkInitStruct.SYSCLKSource = RCC_SYSCLKSOURCE_PLLCLK;
  RCC_ClkInitStruct.SYSCLKDivider = RCC_SYSCLK_DIV1;
  RCC_ClkInitStruct.AHBCLKDivider = RCC_HCLK_DIV2;
  RCC_ClkInitStruct.APB3CLKDivider = RCC_APB3_DIV2;
  RCC_ClkInitStruct.APB1CLKDivider = RCC_APB1_DIV2;
  RCC_ClkInitStruct.APB2CLKDivider = RCC_APB2_DIV2;
  RCC_ClkInitStruct.APB4CLKDivider = RCC_APB4_DIV2;

  if (HAL_RCC_ClockConfig(&RCC_ClkInitStruct, FLASH_LATENCY_4) != HAL_OK)
  {
    Error_Handler();
  }
}

void PeriphCommonClock_Config(void)
{
  RCC_PeriphCLKInitTypeDef PeriphClkInitStruct = {0};

  /** Initializes the peripherals clock
  */
  PeriphClkInitStruct.PeriphClockSelection = RCC_PERIPHCLK_SAI1;
  PeriphClkInitStruct.PLL2.PLL2M = 1;
  PeriphClkInitStruct.PLL2.PLL2N = 50;
  PeriphClkInitStruct.PLL2.PLL2P = 66;
  PeriphClkInitStruct.PLL2.PLL2Q = 2;
  PeriphClkInitStruct.PLL2.PLL2R = 2;
  PeriphClkInitStruct.PLL2.PLL2RGE = RCC_PLL2VCIRANGE_3;
  PeriphClkInitStruct.PLL2.PLL2VCOSEL = RCC_PLL2VCOWIDE;
  PeriphClkInitStruct.PLL2.PLL2FRACN = 5637;
  PeriphClkInitStruct.Sai1ClockSelection = RCC_SAI1CLKSOURCE_PLL2;
  if (HAL_RCCEx_PeriphCLKConfig(&PeriphClkInitStruct) != HAL_OK)
  {
    Error_Handler();
  }
}

void MX_I2C2_Init(void)
{

  hi2c2.Instance = I2C2;
  hi2c2.Init.Timing = 0x307075B1;
  hi2c2.Init.OwnAddress1 = 0;
  hi2c2.Init.AddressingMode = I2C_ADDRESSINGMODE_7BIT;
  hi2c2.Init.DualAddressMode = I2C_DUALADDRESS_DISABLE;
  hi2c2.Init.OwnAddress2 = 0;
  hi2c2.Init.OwnAddress2Masks = I2C_OA2_NOMASK;
  hi2c2.Init.GeneralCallMode = I2C_GENERALCALL_DISABLE;
  hi2c2.Init.NoStretchMode = I2C_NOSTRETCH_DISABLE;
  if (HAL_I2C_Init(&hi2c2) != HAL_OK)
  {
    Error_Handler();
  }

  /** Configure Analogue filter
  */
  if (HAL_I2CEx_ConfigAnalogFilter(&hi2c2, I2C_ANALOGFILTER_ENABLE) != HAL_OK)
  {
    Error_Handler();
  }

  /** Configure Digital filter
  */
  if (HAL_I2CEx_ConfigDigitalFilter(&hi2c2, 0) != HAL_OK)
  {
    Error_Handler();
  }

}

void MX_QUADSPI_Init(void)
{

  /* QUADSPI parameter configuration*/
  hqspi.Instance = QUADSPI;
  hqspi.Init.ClockPrescaler = 2;
  hqspi.Init.FifoThreshold = 1;
  hqspi.Init.SampleShifting = QSPI_SAMPLE_SHIFTING_HALFCYCLE;
  hqspi.Init.FlashSize = 22;
  hqspi.Init.ChipSelectHighTime = QSPI_CS_HIGH_TIME_1_CYCLE;
  hqspi.Init.ClockMode = QSPI_CLOCK_MODE_0;
  hqspi.Init.FlashID = QSPI_FLASH_ID_1;
  hqspi.Init.DualFlash = QSPI_DUALFLASH_DISABLE;
  if (HAL_QSPI_Init(&hqspi) != HAL_OK)
  {
    Error_Handler();
  }

}

void MX_SAI1_Init(void)
{

  hsai_BlockA1.Instance = SAI1_Block_A;
  hsai_BlockA1.Init.AudioMode = SAI_MODEMASTER_TX;
  hsai_BlockA1.Init.Synchro = SAI_ASYNCHRONOUS;
  hsai_BlockA1.Init.OutputDrive = SAI_OUTPUTDRIVE_DISABLE;
  hsai_BlockA1.Init.NoDivider = SAI_MCK_OVERSAMPLING_DISABLE;
  hsai_BlockA1.Init.MckOverSampling = SAI_MCK_OVERSAMPLING_DISABLE;
  hsai_BlockA1.Init.FIFOThreshold = SAI_FIFOTHRESHOLD_EMPTY;
  hsai_BlockA1.Init.AudioFrequency = SAI_AUDIO_FREQUENCY_48K;
  hsai_BlockA1.Init.SynchroExt = SAI_SYNCEXT_DISABLE;
  hsai_BlockA1.Init.MonoStereoMode = SAI_STEREOMODE;
  hsai_BlockA1.Init.CompandingMode = SAI_NOCOMPANDING;
  hsai_BlockA1.Init.TriState = SAI_OUTPUT_NOTRELEASED;
  if (HAL_SAI_InitProtocol(&hsai_BlockA1, SAI_I2S_MSBJUSTIFIED, SAI_PROTOCOL_DATASIZE_24BIT, 2) != HAL_OK)
  {
    Error_Handler();
  }
  hsai_BlockB1.Instance = SAI1_Block_B;
  hsai_BlockB1.Init.AudioMode = SAI_MODESLAVE_RX;
  hsai_BlockB1.Init.Synchro = SAI_SYNCHRONOUS;
  hsai_BlockB1.Init.OutputDrive = SAI_OUTPUTDRIVE_DISABLE;
  hsai_BlockB1.Init.MckOverSampling = SAI_MCK_OVERSAMPLING_DISABLE;
  hsai_BlockB1.Init.FIFOThreshold = SAI_FIFOTHRESHOLD_EMPTY;
  hsai_BlockB1.Init.SynchroExt = SAI_SYNCEXT_DISABLE;
  hsai_BlockB1.Init.MonoStereoMode = SAI_STEREOMODE;
  hsai_BlockB1.Init.CompandingMode = SAI_NOCOMPANDING;
  hsai_BlockB1.Init.TriState = SAI_OUTPUT_NOTRELEASED;
  if (HAL_SAI_InitProtocol(&hsai_BlockB1, SAI_I2S_MSBJUSTIFIED, SAI_PROTOCOL_DATASIZE_24BIT, 2) != HAL_OK)
  {
    Error_Handler();
  }

}

void MX_DMA_Init(void)
{

  /* DMA controller clock enable */
  __HAL_RCC_DMA1_CLK_ENABLE();

  /* DMA interrupt init */
  /* DMA1_Stream0_IRQn interrupt configuration */
  HAL_NVIC_SetPriority(DMA1_Stream0_IRQn, 0, 0);
  HAL_NVIC_EnableIRQ(DMA1_Stream0_IRQn);
  /* DMA1_Stream1_IRQn interrupt configuration */
  HAL_NVIC_SetPriority(DMA1_Stream1_IRQn, 0, 0);
  HAL_NVIC_EnableIRQ(DMA1_Stream1_IRQn);

}

/* FMC initialization function */
void MX_FMC_Init(void)
{

  FMC_SDRAM_TimingTypeDef SdramTiming = {0};

  /** Perform the SDRAM1 memory initialization sequence
  */
  hsdram1.Instance = FMC_SDRAM_DEVICE;
  /* hsdram1.Init */
  hsdram1.Init.SDBank = FMC_SDRAM_BANK1;
  hsdram1.Init.ColumnBitsNumber = FMC_SDRAM_COLUMN_BITS_NUM_9;
  hsdram1.Init.RowBitsNumber = FMC_SDRAM_ROW_BITS_NUM_13;
  hsdram1.Init.MemoryDataWidth = FMC_SDRAM_MEM_BUS_WIDTH_32;
  hsdram1.Init.InternalBankNumber = FMC_SDRAM_INTERN_BANKS_NUM_4;
  hsdram1.Init.CASLatency = FMC_SDRAM_CAS_LATENCY_3;
  hsdram1.Init.WriteProtection = FMC_SDRAM_WRITE_PROTECTION_DISABLE;
  hsdram1.Init.SDClockPeriod = FMC_SDRAM_CLOCK_PERIOD_2;
  hsdram1.Init.ReadBurst = FMC_SDRAM_RBURST_ENABLE;
  hsdram1.Init.ReadPipeDelay = FMC_SDRAM_RPIPE_DELAY_0;
  /* SdramTiming */
  SdramTiming.LoadToActiveDelay = 2;
  SdramTiming.ExitSelfRefreshDelay = 7;
  SdramTiming.SelfRefreshTime = 4;
  SdramTiming.RowCycleDelay = 8;
  SdramTiming.WriteRecoveryTime = 3;
  SdramTiming.RPDelay = 16;
  SdramTiming.RCDDelay = 10;

  if (HAL_SDRAM_Init(&hsdram1, &SdramTiming) != HAL_OK)
  {
    Error_Handler( );
  }

  /* USER CODE BEGIN FMC_Init 2 */
#define SDRAM_MODEREG_BURST_LENGTH_2 ((1 << 0))
#define SDRAM_MODEREG_BURST_LENGTH_4 ((1 << 1))

#define SDRAM_MODEREG_BURST_TYPE_SEQUENTIAL ((0 << 3))

#define SDRAM_MODEREG_CAS_LATENCY_3 ((1 << 4) | (1 << 5))

#define SDRAM_MODEREG_OPERATING_MODE_STANDARD ()

#define SDRAM_MODEREG_WRITEBURST_MODE_SINGLE ((1 << 9))
#define SDRAM_MODEREG_WRITEBURST_MODE_PROG_BURST ((0 << 9))

   FMC_SDRAM_CommandTypeDef Command;

   /* Step 3:  Configure a clock configuration enable command */
   Command.CommandMode            = FMC_SDRAM_CMD_CLK_ENABLE;
   Command.CommandTarget          = FMC_SDRAM_CMD_TARGET_BANK1;
   Command.AutoRefreshNumber      = 1;
   Command.ModeRegisterDefinition = 0;

   /* Send the command */
   if(HAL_SDRAM_SendCommand(&hsdram1, &Command, 0x1000) != HAL_OK){
	    Error_Handler();
   }

   /* Step 4: Insert 100 ms delay */
   HAL_Delay(100);

   /* Step 5: Configure a PALL (precharge all) command */
   Command.CommandMode            = FMC_SDRAM_CMD_PALL;
   Command.CommandTarget          = FMC_SDRAM_CMD_TARGET_BANK1;
   Command.AutoRefreshNumber      = 1;
   Command.ModeRegisterDefinition = 0;

   /* Send the command */
   if(HAL_SDRAM_SendCommand(&hsdram1, &Command, 0x1000) != HAL_OK){
	    Error_Handler();
   }

   /* Step 6 : Configure a Auto-Refresh command */
   Command.CommandMode            = FMC_SDRAM_CMD_AUTOREFRESH_MODE;
   Command.CommandTarget          = FMC_SDRAM_CMD_TARGET_BANK1;
   Command.AutoRefreshNumber      = 4;
   Command.ModeRegisterDefinition = 0;

   /* Send the command */
   if(HAL_SDRAM_SendCommand(&hsdram1, &Command, 0x1000) != HAL_OK){
	    Error_Handler();
   }

   /* Step 7: Program the external memory mode register */
   uint32_t tmpmrd = 0;
   tmpmrd = (uint32_t)SDRAM_MODEREG_BURST_LENGTH_4
            | SDRAM_MODEREG_BURST_TYPE_SEQUENTIAL | SDRAM_MODEREG_CAS_LATENCY_3
            | SDRAM_MODEREG_WRITEBURST_MODE_SINGLE;

   Command.CommandMode            = FMC_SDRAM_CMD_LOAD_MODE;
   Command.CommandTarget          = FMC_SDRAM_CMD_TARGET_BANK1;
   Command.AutoRefreshNumber      = 1;
   Command.ModeRegisterDefinition = tmpmrd;

   /* Send the command */
   if(HAL_SDRAM_SendCommand(&hsdram1, &Command, 0x1000) != HAL_OK){
	    Error_Handler();
   }

   if(HAL_SDRAM_ProgramRefreshRate(&hsdram1, 0x81A - 20) != HAL_OK){
	    Error_Handler();
   }

  /* USER CODE END FMC_Init 2 */
}

void MX_GPIO_Init(void)
{
  GPIO_InitTypeDef GPIO_InitStruct = {0};

  /* GPIO Ports Clock Enable */
  __HAL_RCC_GPIOE_CLK_ENABLE();
  __HAL_RCC_GPIOB_CLK_ENABLE();
  __HAL_RCC_GPIOA_CLK_ENABLE();
  __HAL_RCC_GPIOG_CLK_ENABLE();
  __HAL_RCC_GPIOD_CLK_ENABLE();
  __HAL_RCC_GPIOI_CLK_ENABLE();
  __HAL_RCC_GPIOH_CLK_ENABLE();
  __HAL_RCC_GPIOF_CLK_ENABLE();
  __HAL_RCC_GPIOC_CLK_ENABLE();

  /*Configure GPIO pin Output Level */
  HAL_GPIO_WritePin(LED_GPIO_Port, LED_Pin, GPIO_PIN_RESET);

  /*Configure GPIO pins : Rev7_Pin Rev5_Pin */
  GPIO_InitStruct.Pin = Rev7_Pin|Rev5_Pin;
  GPIO_InitStruct.Mode = GPIO_MODE_INPUT;
  GPIO_InitStruct.Pull = GPIO_PULLUP;
  HAL_GPIO_Init(GPIOD, &GPIO_InitStruct);

  /*Configure GPIO pin : LED_Pin */
  GPIO_InitStruct.Pin = LED_Pin;
  GPIO_InitStruct.Mode = GPIO_MODE_OUTPUT_PP;
  GPIO_InitStruct.Pull = GPIO_NOPULL;
  GPIO_InitStruct.Speed = GPIO_SPEED_FREQ_LOW;
  HAL_GPIO_Init(LED_GPIO_Port, &GPIO_InitStruct);

}

void Error_Handler(void)
{
  __disable_irq();
  while (1)
  {
  }
}
